# M451_v1 register map
File version: 1.0
Registers are 32-bit, read-write, reset 0x0 unless marked. A register's access mark holds for its fields unless they carry their own. Offsets are from the block's base; [hi:lo] are bit positions; {n}, {i} and the like mark numbered series.

## CRC — CRC Register Map
Base 0x40031000
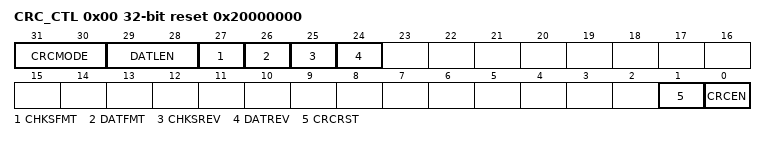
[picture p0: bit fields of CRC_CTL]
0x00 CRC_CTL reset 0x20000000 — CRC Control Register
  [31:30] CRCMODE — CRC Polynomial Mode. This field indicates the CRC operation polynomial mode.
    0=CRC-CCITT Polynomial mode; 1=CRC-8 Polynomial mode; 2=CRC-16 Polynomial mode; 3=CRC-32 Polynomial mode
  [29:28] DATLEN — CPU Write Data Length. This field indicates the write data length. Note: When the write data length is 8-bit mode, the valid data in CRC_DAT register is only DATA[7:0] bits; if the write data length is 16-bit mode, the valid data in CRC_DAT register is only DATA[15:0].
    0=Data length is 8-bit mode; 1=Data length is 16-bit mode. Data length is 32-bit mode
  [27] CHKSFMT — Checksum 1's Complement. This bit is used to enable the 1's complement function for checksum result in CRC_CHECKSUM register.
    0=1's complement for CRC checksum Disabled; 1=1's complement for CRC checksum Enabled
  [26] DATFMT — Write Data 1's Complement. This bit is used to enable the 1's complement function for write data value in CRC_DAT register.
    0=1's complement for CRC writes data in Disabled; 1=1's complement for CRC writes data in Enabled
  [25] CHKSREV — Checksum Bit Order Reverse. This bit is used to enable the bit order reverse function for write data value in CRC_CHECKSUM register. Note: If the checksum result is 0xDD7B0F2E, the bit order reverse for CRC checksum is 0x74F0DEBB.
    0=Bit order reverse for CRC checksum Disabled; 1=Bit order reverse for CRC checksum Enabled
  [24] DATREV — Write Data Bit Order Reverse. This bit is used to enable the bit order reverse function for write data value in CRC_DAT register. Note: If the write data is 0xAABBCCDD, the bit order reverse for CRC write data is 0x55DD33BB.
    0=Bit order reversed for CRC write data in Disabled; 1=Bit order reversed for CRC write data in Enabled (per byte)
  [1] CRCRST — CRC Engine Reset. Note1: This bit will be cleared automatically. Note2: Setting this bit will reload the seed value from CRC_SEED register as checksum initial vale.
    0=No effect; 1=Reset the internal CRC state machine. The others contents of CRC_CTL register will not be cleared
  [0] CRCEN — CRC Channel Enable Bit
    0=No effect; 1=CRC operation Enabled
0x04 CRC_DAT — CRC Write Data Register
  [31:0] DATA — CRC Write Data Bits. User can write data directly by CPU mode or use PDMA function to write data to this field to perform CRC operation. Note: When the write data length is 8-bit mode, the valid data in CRC_DAT register is only DATA[7:0] bits; if the write data length is 16-bit mode, the valid data in CRC_DAT register is only DATA[15:0].
0x08 CRC_SEED reset 0xFFFFFFFF
  [31:0] SEED — CRC Seed Value. This field indicates the CRC seed value.
0x0C CRC_CHECKSUM ro
  [31:0] CHECKSUM — CRC Checksum Results. This field indicates the CRC checksum result.

## DAC — DAC Register Map
Base 0x40047000
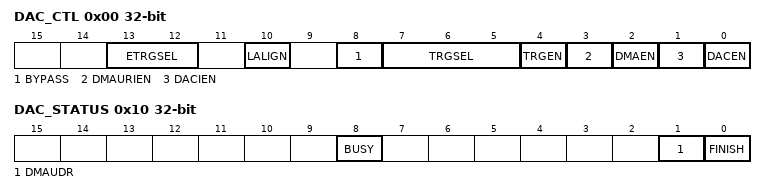
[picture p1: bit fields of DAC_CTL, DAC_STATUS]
0x00 DAC_CTL — DAC Control Register
  [13:12] ETRGSEL — External Pin Trigger Selection
    0=Low level trigger; 1=High level trigger; 2=Falling edge trigger; 3=Rising edge trigger
  [10] LALIGN — DAC Data Left-aligned Enabled Control
    0=Right alignment; 1=Left alignment
  [8] BYPASS — Bypass Buffer Mode
    0=Output voltage buffer Enabled; 1=Output voltage buffer Disabled
  [7:5] TRGSEL — Trigger Source Selection
    0=Software trigger; 1=External pin STDAC trigger; {v}=Timer {v-2} trigger (v=2..5); 6=PWM0 trigger; 7=PWM1 trigger
  [4] TRGEN — Trigger Mode Enable Bit
    0=DAC event trigger mode Disabled; 1=DAC event trigger mode Enabled
  [3] DMAURIEN — DMA Under-run Interrupt Enable Bit
    0=DMA underrun interrupt Disabled; 1=DMA underrun interrupt Enabled
  [2] DMAEN — DMA Mode Enable Bit
    0=DMA mode Disabled; 1=DMA mode Enabled
  [1] DACIEN — DAC Interrupt Enable Bit
    0=Interrupt is Disabled; 1=Interrupt is Enabled
  [0] DACEN — DAC Enable Bit
    0=DAC is Disabled; 1=DAC is Enabled
0x04 DAC_SWTRG — DAC Software Trigger Control Register
  [0] SWTRG — Software Trigger. User writes this bit to generate one shot pulse and it is cleared to 0 by hardware automatically; Reading this bit will always get 0.
    0=Software trigger Disabled; 1=Software trigger Enabled
0x08 DAC_DAT — DAC Data Holding Register
  [15:0] DAC_DAT — DAC 12-bit Holding Data. These bits are written by user software which specifies 12-bit conversion data for DAC output. The unused bits (DAC_DAT[3:0] in left-alignment mode and DAC_DAT[15:12] in right alignment mode) are ignored by DAC controller hardware. 12 bit left alignment: user has to load data into DAC_DAT[15:4] bits. 12 bit right alignment: user has to load data into DAC_DAT[11:0] bits.
0x0C DAC_DATOUT ro — DAC Data Output Register
  [11:0] DATOUT — DAC 12-bit Output Data. These bits are current digital data for DAC output conversion. It is loaded from DAC_DAT register and user cannot write it directly.
0x10 DAC_STATUS
  [8] BUSY ro — DAC Busy Flag (Read Only). This is read only bit.
    0=DAC is ready for next conversion; 1=DAC is busy in conversion
  [1] DMAUDR — DMA Under Run Interrupt Flag. User writes 1 to clear this bit.
    0=No DMA under-run error condition occurred; 1=DMA under-run error condition occurred
  [0] FINISH — DAC Conversion Complete Finish Flag. This bit set to 1 when conversion time counter counts to SETTLET. It is cleared to 0 when DAC starts a new conversion. User writes 1 to clear this bit to 0.
    0=DAC is in conversion state; 1=DAC conversion finish
0x14 DAC_TCTL — DAC Timing Control Register
  [9:0] SETTLET — DAC Output Settling Time. User software needs to write appropriate value to these bits to meet DAC conversion settling time base on PCLK (APB clock) speed. For example, DAC controller clock speed is 72MHz and DAC conversion setting time is 1 us, SETTLET value must be greater than 0x48.
